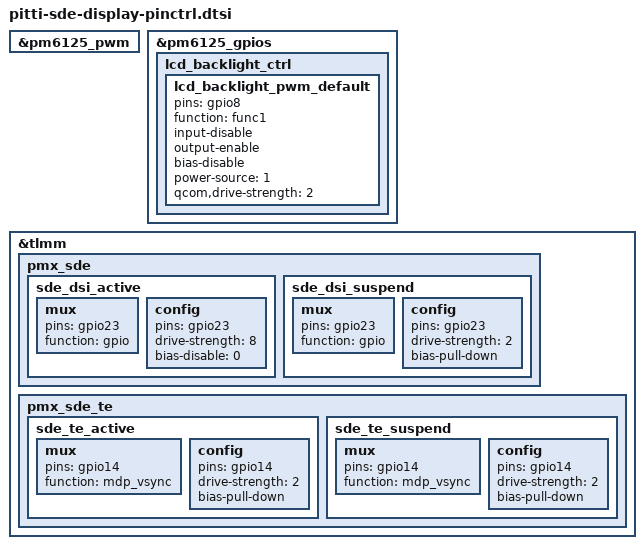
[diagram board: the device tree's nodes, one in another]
&pm6125_pwm {
	status = "ok";
};

&pm6125_gpios {
	lcd_backlight_ctrl {
		lcd_backlight_pwm_default: lcd_backlight_pwm_default {
			pins = "gpio8";
			function = "func1";
			input-disable;
			output-enable;
			bias-disable;
			power-source = <1>;       /* 1.8V */
			qcom,drive-strength = <2>;
		};
	};
};

&tlmm {
	pmx_sde: pmx_sde {
		sde_dsi_active: sde_dsi_active {
			mux {
				pins = "gpio23";
				function = "gpio";
			};

			config {
				pins = "gpio23";
				drive-strength = <8>;   /* 8 mA */
				bias-disable = <0>;   /* no pull */
			};
		};

		sde_dsi_suspend: sde_dsi_suspend {
			mux {
				pins = "gpio23";
				function = "gpio";
			};

			config {
				pins = "gpio23";
				drive-strength = <2>;   /* 2 mA */
				bias-pull-down;         /* PULL DOWN */
			};
		};
	};

	pmx_sde_te: pmx_sde_te {
		sde_te_active: sde_te_active {
			mux {
				pins = "gpio14";
				function = "mdp_vsync";
			};

			config {
				pins = "gpio14";
				drive-strength = <2>;   /* 2 mA */
				bias-pull-down;         /* PULL DOWN */
			};
		};

		sde_te_suspend: sde_te_suspend {
			mux {
				pins = "gpio14";
				function = "mdp_vsync";
			};

			config {
				pins = "gpio14";
				drive-strength = <2>;   /* 2 mA */
				bias-pull-down;         /* PULL DOWN */
			};
		};
	};
};
